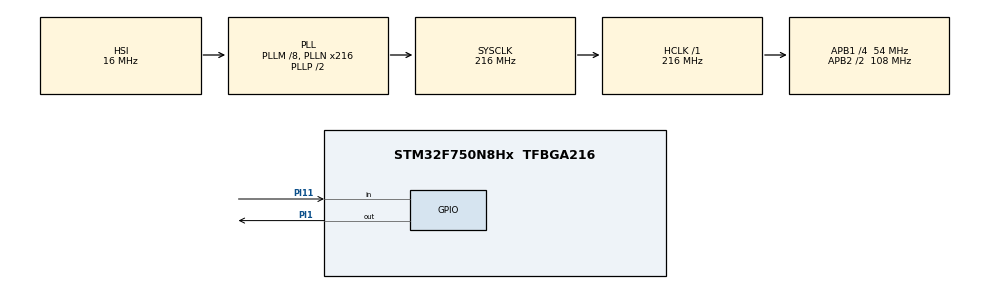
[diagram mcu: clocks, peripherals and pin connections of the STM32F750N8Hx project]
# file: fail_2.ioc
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Mcu.Family=STM32F7
Mcu.Name=STM32F750N8Hx
Mcu.Package=TFBGA216
NVIC.PriorityGroup=NVIC_PRIORITYGROUP_4
PA13.Signal=SYS_JTMS-SWDIO
PA14.Signal=SYS_JTCK-SWCLK
PI1.Signal=GPIO_Output
PI11.Signal=GPIO_Input
ProjectManager.HeapSize=0x200
ProjectManager.StackSize=0x400
ProjectManager.TargetToolchain=STM32CubeIDE
RCC.AHBFreq_Value=216000000
RCC.APB1CLKDivider=RCC_HCLK_DIV4
RCC.APB1Freq_Value=54000000
RCC.APB1TimFreq_Value=108000000
RCC.APB2CLKDivider=RCC_HCLK_DIV2
RCC.APB2Freq_Value=108000000
RCC.APB2TimFreq_Value=216000000
RCC.CortexFreq_Value=216000000
RCC.HCLKFreq_Value=216000000
RCC.HSE_VALUE=25000000
RCC.HSI_VALUE=16000000
RCC.LSE_VALUE=32768
RCC.PLL48CLockSelection=RCC_CLK48SOURCE_PLLSAIP
RCC.PLLI2SN=100
RCC.PLLM=8
RCC.PLLN=216
RCC.PLLQ=9
RCC.PLLSAIN=384
RCC.PLLSAIP=RCC_PLLSAIP_DIV8
RCC.PLLSAIR=5
RCC.SDMMCClockSelection=RCC_SDMMC1CLKSOURCE_CLK48
RCC.SYSCLKFreq_VALUE=216000000
RCC.SYSCLKSource=RCC_SYSCLKSOURCE_PLLCLK
RCC.USBFreq_Value=96000000
RCC.VCOOutputFreq_Value=432000000
board=STM32F7508-DK

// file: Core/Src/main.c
/* USER CODE BEGIN Header */
/**
  ******************************************************************************
  * @file           : main.c
  * @brief          : Main program body
  ******************************************************************************
  * @attention
  *
  * <h2><center>&copy; Copyright (c) 2021 STMicroelectronics.
  * All rights reserved.</center></h2>
  *
  * This software component is licensed by ST under Ultimate Liberty license
  * SLA0044, the "License"; You may not use this file except in compliance with
  * the License. You may obtain a copy of the License at:
  *                             www.st.com/SLA0044
  *
  ******************************************************************************
  */
/* USER CODE END Header */
#include "main.h"

void SystemClock_Config(void);
static void MX_GPIO_Init(void);

int main(void)
{

  /* MCU Configuration--------------------------------------------------------*/

  /* Reset of all peripherals, Initializes the Flash interface and the Systick. */
  HAL_Init();

  /* Configure the system clock */
  SystemClock_Config();

  /* Initialize all configured peripherals */
  MX_GPIO_Init();
  /* USER CODE BEGIN 2 */
  int prev_st = 0;

  /* USER CODE END 2 */

  /* Infinite loop */
  /* USER CODE BEGIN WHILE */
  while (1)
  {
	  //HAL_GPIO_WritePin(GPIOI, GPIO_PIN_1, GPIO_PIN_RESET);
	  HAL_GPIO_TogglePin(GPIOI, GPIO_PIN_1);
	  HAL_Delay(500);

//	  button_st = HAL_GPIO_ReadPin(GPIOI, GPIO_PIN_11);
//	  if(button_st == 1){
//		  HAL_GPIO_TogglePin(GPIOI, GPIO_PIN_1);
////		  HAL_GPIO_WritePin(GPIOI, GPIO_PIN_1, button_st & 1);
////		  HAL_Delay(1000);
//	  }
//	  else HAL_GPIO_WritePin(GPIOI, GPIO_PIN_1, button_st & 0);
/*
	        if(HAL_GPIO_ReadPin (GPIOI, GPIO_PIN_11))
	        {
	        	HAL_Delay(100);
	        	if(prev_st == 0){
	        		HAL_GPIO_WritePin(GPIOI, GPIO_PIN_1, GPIO_PIN_SET);
	        		prev_st = 1;
	        	}
	        	else{
	        		HAL_GPIO_WritePin(GPIOI, GPIO_PIN_1, GPIO_PIN_RESET);
	        		prev_st = 0;

	        	}

	            // Set The LED ON!
//	            HAL_GPIO_WritePin(GPIOI, GPIO_PIN_1, GPIO_PIN_SET);
	        	HAL_GPIO_TogglePin(GPIOI, GPIO_PIN_1);
	        }
//	        else
//	        {
//	            // Else .. Turn LED OFF!
//	            HAL_GPIO_WritePin(GPIOI, GPIO_PIN_1, GPIO_PIN_RESET);
//	        }
*/

    /* USER CODE END WHILE */

  }
}

void SystemClock_Config(void)
{
  RCC_OscInitTypeDef RCC_OscInitStruct = {0};
  RCC_ClkInitTypeDef RCC_ClkInitStruct = {0};

  /** Configure the main internal regulator output voltage
  */
  __HAL_RCC_PWR_CLK_ENABLE();
  __HAL_PWR_VOLTAGESCALING_CONFIG(PWR_REGULATOR_VOLTAGE_SCALE1);
  /** Initializes the RCC Oscillators according to the specified parameters
  * in the RCC_OscInitTypeDef structure.
  */
  RCC_OscInitStruct.OscillatorType = RCC_OSCILLATORTYPE_HSI;
  RCC_OscInitStruct.HSIState = RCC_HSI_ON;
  RCC_OscInitStruct.HSICalibrationValue = RCC_HSICALIBRATION_DEFAULT;
  RCC_OscInitStruct.PLL.PLLState = RCC_PLL_ON;
  RCC_OscInitStruct.PLL.PLLSource = RCC_PLLSOURCE_HSI;
  RCC_OscInitStruct.PLL.PLLM = 8;
  RCC_OscInitStruct.PLL.PLLN = 216;
  RCC_OscInitStruct.PLL.PLLP = RCC_PLLP_DIV2;
  RCC_OscInitStruct.PLL.PLLQ = 9;
  if (HAL_RCC_OscConfig(&RCC_OscInitStruct) != HAL_OK)
  {
    Error_Handler();
  }
  /** Activate the Over-Drive mode
  */
  if (HAL_PWREx_EnableOverDrive() != HAL_OK)
  {
    Error_Handler();
  }
  /** Initializes the CPU, AHB and APB buses clocks
  */
  RCC_ClkInitStruct.ClockType = RCC_CLOCKTYPE_HCLK|RCC_CLOCKTYPE_SYSCLK
                              |RCC_CLOCKTYPE_PCLK1|RCC_CLOCKTYPE_PCLK2;
  RCC_ClkInitStruct.SYSCLKSource = RCC_SYSCLKSOURCE_PLLCLK;
  RCC_ClkInitStruct.AHBCLKDivider = RCC_SYSCLK_DIV1;
  RCC_ClkInitStruct.APB1CLKDivider = RCC_HCLK_DIV4;
  RCC_ClkInitStruct.APB2CLKDivider = RCC_HCLK_DIV2;

  if (HAL_RCC_ClockConfig(&RCC_ClkInitStruct, FLASH_LATENCY_7) != HAL_OK)
  {
    Error_Handler();
  }
}

static void MX_GPIO_Init(void)
{
  GPIO_InitTypeDef GPIO_InitStruct = {0};

  /* GPIO Ports Clock Enable */
  __HAL_RCC_GPIOA_CLK_ENABLE();
  __HAL_RCC_GPIOI_CLK_ENABLE();

  /*Configure GPIO pin Output Level */
  HAL_GPIO_WritePin(GPIOI, GPIO_PIN_1, GPIO_PIN_RESET);

  /*Configure GPIO pin : PI1 */
  GPIO_InitStruct.Pin = GPIO_PIN_1;
  GPIO_InitStruct.Mode = GPIO_MODE_OUTPUT_PP;
  GPIO_InitStruct.Pull = GPIO_NOPULL;
  GPIO_InitStruct.Speed = GPIO_SPEED_FREQ_LOW;
  HAL_GPIO_Init(GPIOI, &GPIO_InitStruct);

  /*Configure GPIO pin : PI11 */
  GPIO_InitStruct.Pin = GPIO_PIN_11;
  GPIO_InitStruct.Mode = GPIO_MODE_INPUT;
  GPIO_InitStruct.Pull = GPIO_NOPULL;
  HAL_GPIO_Init(GPIOI, &GPIO_InitStruct);

}

void Error_Handler(void)
{
  __disable_irq();
  while (1)
  {
  }
}

/************************ (C) COPYRIGHT STMicroelectronics *****END OF FILE****/
